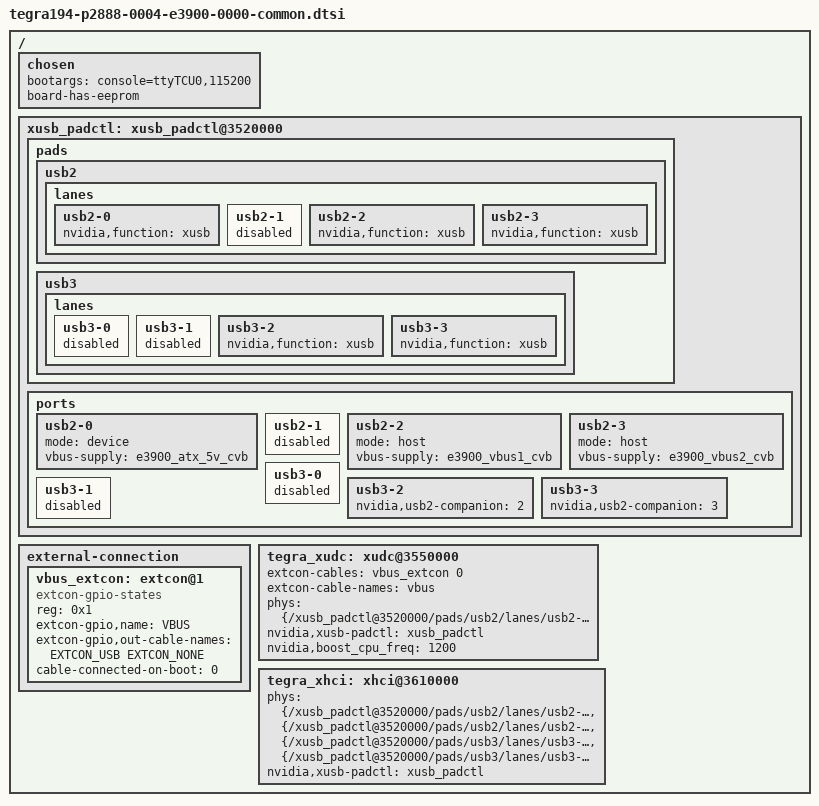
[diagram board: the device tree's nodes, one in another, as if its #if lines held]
/*
 * Common include DTS file for CVM:P2888-0004 and CVB:E3900-0000 variants.
 *
 * Copyright (c) 2019-2020, NVIDIA CORPORATION.  All rights reserved.
 *
 * This program is free software; you can redistribute it and/or modify
 * it under the terms of the GNU General Public License as published by
 * the Free Software Foundation; version 2 of the License.
 *
 * This program is distributed in the hope that it will be useful, but WITHOUT
 * ANY WARRANTY; without even the implied warranty of MERCHANTABILITY or
 * FITNESS FOR A PARTICULAR PURPOSE.  See the GNU General Public License for
 * more details.
 */

#include <galen/kernel-dts/common/tegra194-p2888-0001-p2822-0000-common.dtsi>
#include "tegra194-audio-e3900-0000.dtsi"
#include "tegra194-super-module-e2614-e3900-0000.dtsi"

/ {
        chosen {
                bootargs ="console=ttyTCU0,115200";
                board-has-eeprom;
        };

#if TEGRA_XUSB_PADCONTROL_VERSION >= DT_VERSION_2

	xusb_padctl: xusb_padctl@3520000 {
		status = "okay";

		pads {
			usb2 {
				lanes {
					usb2-0 {
						nvidia,function = "xusb";
						status = "okay";
					};
					usb2-1 {
						status = "disabled";
					};
					usb2-2 {
						nvidia,function = "xusb";
						status = "okay";
					};
					usb2-3 {
						nvidia,function = "xusb";
						status = "okay";
					};
				};
			};
			usb3 {
				lanes {
					usb3-0 {
						status = "disabled";
					};
					usb3-1 {
						status = "disabled";
					};
					usb3-2 {
						nvidia,function = "xusb";
						status = "okay";
					};
					usb3-3 {
						nvidia,function = "xusb";
						status = "okay";
					};
				};
			};
		};

		ports {
			usb2-0 {
				mode = "device";
				vbus-supply = <&e3900_atx_5v_cvb>;
				status = "okay";
			};
			usb2-1 {
				status = "disabled";
			};
			usb2-2 {
				mode = "host";
				vbus-supply = <&e3900_vbus1_cvb>;
				status = "okay";
			};
			usb2-3 {
				mode = "host";
				vbus-supply = <&e3900_vbus2_cvb>;
				status = "okay";
			};
			usb3-0 {
				status = "disabled";
			};
			usb3-1 {
				status = "disabled";
			};
			usb3-2 {
				nvidia,usb2-companion = <2>;
				/delete-property/ nvidia,usb3-gen1-only;
				status = "okay";
			};
			usb3-3 {
				nvidia,usb2-companion = <3>;
				/delete-property/ nvidia,usb3-gen1-only;
				status = "okay";
			};
		};
	};
#endif

	external-connection {
		vbus_extcon: extcon@1 {
			compatible = "extcon-gpio-states";
			reg = <0x1>;
			extcon-gpio,name = "VBUS";
			/delete-property/ extcon-gpio,wait-for-gpio-scan;
			/delete-property/ extcon-gpio,cable-states;
			/delete-property/ gpios;
			extcon-gpio,out-cable-names = <EXTCON_USB EXTCON_NONE>;
			cable-connected-on-boot = <0>;
			#extcon-cells = <1>;
			status = "okay";
		};
	};

	tegra_xudc: xudc@3550000 {
		extcon-cables = <&vbus_extcon 0>;
		extcon-cable-names = "vbus";
		#extcon-cells = <1>;
#if TEGRA_XUSB_PADCONTROL_VERSION >= DT_VERSION_2
		phys = <&{/xusb_padctl@3520000/pads/usb2/lanes/usb2-0}>;
		phy-names = "usb2";
		nvidia,xusb-padctl = <&xusb_padctl>;
#endif
		nvidia,boost_cpu_freq = <1200>;
		status = "okay";
	};

	tegra_xhci: xhci@3610000 {
		/delete-property/ extcon-cables;
		/delete-property/ extcon-cable-names;
#if TEGRA_XUSB_PADCONTROL_VERSION >= DT_VERSION_2
		phys = <&{/xusb_padctl@3520000/pads/usb2/lanes/usb2-2}>,
			<&{/xusb_padctl@3520000/pads/usb2/lanes/usb2-3}>,
			<&{/xusb_padctl@3520000/pads/usb3/lanes/usb3-2}>,
			<&{/xusb_padctl@3520000/pads/usb3/lanes/usb3-3}>;
		phy-names = "usb2-2", "usb2-3", "usb3-2", "usb3-3";
		nvidia,xusb-padctl = <&xusb_padctl>;
#endif
		status = "okay";
	};
};
